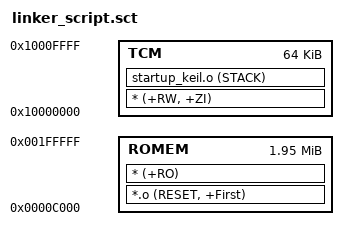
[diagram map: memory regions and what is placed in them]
;******************************************************************************
;
; Scatter file for Keil linker configuration.
;
;******************************************************************************
LR_1 0x0000C000
{
    ROMEM 0x0000C000 0x001F4000
    {
        *.o (RESET, +First)
        * (+RO)
    }

    TCM 0x10000000 0x00010000
    {
        * (+RW, +ZI)
		startup_keil.o (STACK)
    }
}
